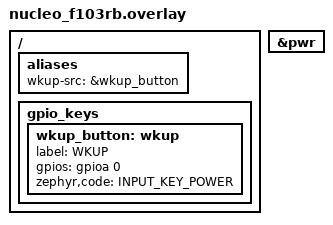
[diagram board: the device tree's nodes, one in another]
/*
 * Copyright (c) 2025 Oleh Kravchenko <oleh@kaa.org.ua>
 *
 * SPDX-License-Identifier: Apache-2.0
 */

/ {
	aliases {
		wkup-src = &wkup_button;
	};

	gpio_keys {
		/*
		 * PA0 is not connected to any button: you
		 * must connect it to Vdd using a jumper wire.
		 * (N.B.: PA0 is Arduino "A0"; Vdd is "+3.3V")
		 */
		wkup_button: wkup {
			label = "WKUP";
			gpios = <&gpioa 0 (GPIO_ACTIVE_HIGH | GPIO_PULL_DOWN)>;
			zephyr,code = <INPUT_KEY_POWER>;
		};
	};
};

&pwr {
	status = "okay";
};
